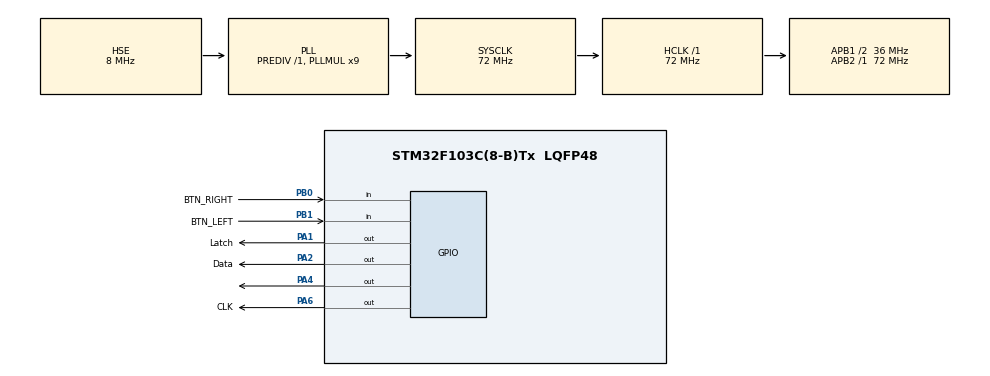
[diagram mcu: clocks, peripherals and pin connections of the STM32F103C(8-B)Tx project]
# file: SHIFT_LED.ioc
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Mcu.Family=STM32F1
Mcu.Name=STM32F103C(8-B)Tx
Mcu.Package=LQFP48
NVIC.PriorityGroup=NVIC_PRIORITYGROUP_4
PA1.GPIO_Label=Latch
PA1.Signal=GPIO_Output
PA13.Mode=Serial_Wire
PA13.Signal=SYS_JTMS-SWDIO
PA14.Mode=Serial_Wire
PA14.Signal=SYS_JTCK-SWCLK
PA2.GPIO_Label=Data
PA2.Signal=GPIO_Output
PA4.Signal=GPIO_Output
PA6.GPIO_Label=CLK
PA6.Signal=GPIO_Output
PB0.GPIO_Label=BTN_RIGHT
PB0.GPIO_PuPd=GPIO_PULLUP
PB0.Signal=GPIO_Input
PB1.GPIO_Label=BTN_LEFT
PB1.GPIO_PuPd=GPIO_PULLUP
PB1.Signal=GPIO_Input
PD0-OSC_IN.Mode=HSE-External-Oscillator
PD0-OSC_IN.Signal=RCC_OSC_IN
PD1-OSC_OUT.Mode=HSE-External-Oscillator
PD1-OSC_OUT.Signal=RCC_OSC_OUT
ProjectManager.HeapSize=0x200
ProjectManager.StackSize=0x400
ProjectManager.TargetToolchain=STM32CubeIDE
RCC.AHBFreq_Value=72000000
RCC.APB1CLKDivider=RCC_HCLK_DIV2
RCC.APB1Freq_Value=36000000
RCC.APB1TimFreq_Value=72000000
RCC.APB2Freq_Value=72000000
RCC.APB2TimFreq_Value=72000000
RCC.HCLKFreq_Value=72000000
RCC.PLLMUL=RCC_PLL_MUL9
RCC.PLLSourceVirtual=RCC_PLLSOURCE_HSE
RCC.RCC_MCOSource=RCC_MCO1SOURCE_PLLCLK
RCC.SYSCLKFreq_VALUE=72000000
RCC.SYSCLKSource=RCC_SYSCLKSOURCE_PLLCLK
RCC.USBFreq_Value=72000000
board=custom

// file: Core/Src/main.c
/* USER CODE BEGIN Header */
/**
  ******************************************************************************
  * @file           : main.c
  * @brief          : Main program body
  ******************************************************************************
  * @attention
  *
  * Copyright (c) 2025 STMicroelectronics.
  * All rights reserved.
  *
  * This software is licensed under terms that can be found in the LICENSE file
  * in the root directory of this software component.
  * If no LICENSE file comes with this software, it is provided AS-IS.
  *
  ******************************************************************************
  */
/* USER CODE END Header */
#include "main.h"

/* USER CODE BEGIN PV */
uint8_t myByte = 0b00010000;
/* USER CODE END PV */

void SystemClock_Config(void);
static void MX_GPIO_Init(void);

/* USER CODE BEGIN 0 */
void HC595write(){
	// Inner loop: Iterates 8 times (for each bit of 'myByte')
	  for(int i = 0; i < 8; i++){
		  // Check if the i-th bit of 'myByte' is set
		  if(myByte & (1<<i)){ // (1<<i) creates a bitmask (1, 2, 4, 8, 16, 32, 64, 128)
			  // If the bit is set, set GPIOA_PIN_2 HIGH
			  HAL_GPIO_WritePin(GPIOA, GPIO_PIN_2, GPIO_PIN_SET);
		  }else{
			  // If the bit is not set, set GPIOA_PIN_2 LOW
			  HAL_GPIO_WritePin(GPIOA, GPIO_PIN_2, GPIO_PIN_RESET);
		  }
		  // Pulse GPIOA_PIN_6 (set HIGH then immediately LOW)
		  HAL_GPIO_WritePin(GPIOA, GPIO_PIN_6, GPIO_PIN_SET);
		  HAL_GPIO_WritePin(GPIOA, GPIO_PIN_6, GPIO_PIN_RESET);
	  }
	  // After iterating through all 8 bits of 'myByte', pulse GPIOA_PIN_1
	  HAL_GPIO_WritePin(GPIOA, GPIO_PIN_1, GPIO_PIN_SET);
	  HAL_GPIO_WritePin(GPIOA, GPIO_PIN_1, GPIO_PIN_RESET);
}

void BTN_left(){

}
/* USER CODE END 0 */

int main(void)
{

  /* MCU Configuration--------------------------------------------------------*/

  /* Reset of all peripherals, Initializes the Flash interface and the Systick. */
  HAL_Init();

  /* Configure the system clock */
  SystemClock_Config();

  /* Initialize all configured peripherals */
  MX_GPIO_Init();

  GPIO_PinState prevButtonStateLeft = HAL_GPIO_ReadPin(GPIOB, GPIO_PIN_1);
  GPIO_PinState prevButtonStateRight = HAL_GPIO_ReadPin(GPIOB, GPIO_PIN_0);

  /* Infinite loop */
  /* USER CODE BEGIN WHILE */
  while (1)
  {
	  HC595write();

	  GPIO_PinState currButtonStateLeft = HAL_GPIO_ReadPin(GPIOB, GPIO_PIN_1);
	  GPIO_PinState currButtonStateRight = HAL_GPIO_ReadPin(GPIOB, GPIO_PIN_0);

	  if(currButtonStateLeft != prevButtonStateLeft){
		  HAL_Delay(50);

		  currButtonStateLeft = HAL_GPIO_ReadPin(GPIOB, GPIO_PIN_1);

		  prevButtonStateLeft = currButtonStateLeft;

		  if(currButtonStateLeft == GPIO_PIN_RESET){
			  myByte = (myByte == 0b10000000) ? 0b00000001 : myByte << 1;
		  }
	  }

	  if(currButtonStateRight != prevButtonStateRight){
		  HAL_Delay(50);

		  currButtonStateRight = HAL_GPIO_ReadPin(GPIOB, GPIO_PIN_0);

		  prevButtonStateRight = currButtonStateRight;

		  if(currButtonStateRight == GPIO_PIN_RESET){
			  myByte = (myByte == 0b00000001) ? 0b10000000 : myByte >> 1;
		  }
	  }
  	}
  /* USER CODE END 3 */
}

void SystemClock_Config(void)
{
  RCC_OscInitTypeDef RCC_OscInitStruct = {0};
  RCC_ClkInitTypeDef RCC_ClkInitStruct = {0};

  /** Initializes the RCC Oscillators according to the specified parameters
  * in the RCC_OscInitTypeDef structure.
  */
  RCC_OscInitStruct.OscillatorType = RCC_OSCILLATORTYPE_HSE;
  RCC_OscInitStruct.HSEState = RCC_HSE_ON;
  RCC_OscInitStruct.HSEPredivValue = RCC_HSE_PREDIV_DIV1;
  RCC_OscInitStruct.HSIState = RCC_HSI_ON;
  RCC_OscInitStruct.PLL.PLLState = RCC_PLL_ON;
  RCC_OscInitStruct.PLL.PLLSource = RCC_PLLSOURCE_HSE;
  RCC_OscInitStruct.PLL.PLLMUL = RCC_PLL_MUL9;
  if (HAL_RCC_OscConfig(&RCC_OscInitStruct) != HAL_OK)
  {
    Error_Handler();
  }

  /** Initializes the CPU, AHB and APB buses clocks
  */
  RCC_ClkInitStruct.ClockType = RCC_CLOCKTYPE_HCLK|RCC_CLOCKTYPE_SYSCLK
                              |RCC_CLOCKTYPE_PCLK1|RCC_CLOCKTYPE_PCLK2;
  RCC_ClkInitStruct.SYSCLKSource = RCC_SYSCLKSOURCE_PLLCLK;
  RCC_ClkInitStruct.AHBCLKDivider = RCC_SYSCLK_DIV1;
  RCC_ClkInitStruct.APB1CLKDivider = RCC_HCLK_DIV2;
  RCC_ClkInitStruct.APB2CLKDivider = RCC_HCLK_DIV1;

  if (HAL_RCC_ClockConfig(&RCC_ClkInitStruct, FLASH_LATENCY_2) != HAL_OK)
  {
    Error_Handler();
  }
}

static void MX_GPIO_Init(void)
{
  GPIO_InitTypeDef GPIO_InitStruct = {0};

  /* GPIO Ports Clock Enable */
  __HAL_RCC_GPIOD_CLK_ENABLE();
  __HAL_RCC_GPIOA_CLK_ENABLE();
  __HAL_RCC_GPIOB_CLK_ENABLE();

  /*Configure GPIO pin Output Level */
  HAL_GPIO_WritePin(GPIOA, Latch_Pin|Data_Pin|GPIO_PIN_4|CLK_Pin, GPIO_PIN_RESET);

  /*Configure GPIO pins : Latch_Pin Data_Pin PA4 CLK_Pin */
  GPIO_InitStruct.Pin = Latch_Pin|Data_Pin|GPIO_PIN_4|CLK_Pin;
  GPIO_InitStruct.Mode = GPIO_MODE_OUTPUT_PP;
  GPIO_InitStruct.Pull = GPIO_NOPULL;
  GPIO_InitStruct.Speed = GPIO_SPEED_FREQ_LOW;
  HAL_GPIO_Init(GPIOA, &GPIO_InitStruct);

  /*Configure GPIO pins : BTN_RIGHT_Pin BTN_LEFT_Pin */
  GPIO_InitStruct.Pin = BTN_RIGHT_Pin|BTN_LEFT_Pin;
  GPIO_InitStruct.Mode = GPIO_MODE_INPUT;
  GPIO_InitStruct.Pull = GPIO_PULLUP;
  HAL_GPIO_Init(GPIOB, &GPIO_InitStruct);

}

void Error_Handler(void)
{
  __disable_irq();
  while (1)
  {
  }
}
